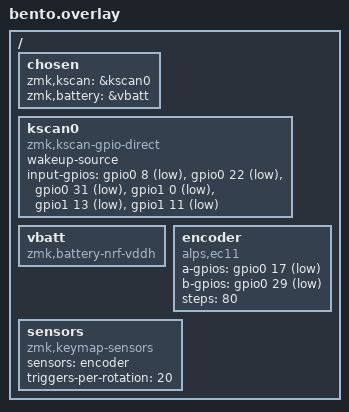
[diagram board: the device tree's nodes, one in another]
/ {
    chosen {
        zmk,kscan = &kscan0;
        zmk,battery = &vbatt;
    };

    kscan0: kscan0 {
        compatible = "zmk,kscan-gpio-direct", "zmk,soft-off-wakeup-sources", "zmk,gpio-key-wakeup-trigger";
        wakeup-source;
        input-gpios
            = <&gpio0 8  (GPIO_ACTIVE_LOW | GPIO_PULL_UP)>
            , <&gpio0 22 (GPIO_ACTIVE_LOW | GPIO_PULL_UP)>
            , <&gpio0 31 (GPIO_ACTIVE_LOW | GPIO_PULL_UP)>
            , <&gpio1 0  (GPIO_ACTIVE_LOW | GPIO_PULL_UP)>
            , <&gpio1 13 (GPIO_ACTIVE_LOW | GPIO_PULL_UP)>
            , <&gpio1 11 (GPIO_ACTIVE_LOW | GPIO_PULL_UP)>
            ;
    };

    vbatt: vbatt {
        compatible = "zmk,battery-nrf-vddh";
    };

    encoder: encoder {
        compatible = "alps,ec11";
        a-gpios = <&gpio0 17 (GPIO_ACTIVE_LOW | GPIO_PULL_UP)>;
        b-gpios = <&gpio0 29 (GPIO_ACTIVE_LOW | GPIO_PULL_UP)>;
        steps = <80>;
        status = "okay";
    };

    sensors: sensors {
        compatible = "zmk,keymap-sensors";
        sensors = <&encoder>;
        triggers-per-rotation = <20>;
    };
};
